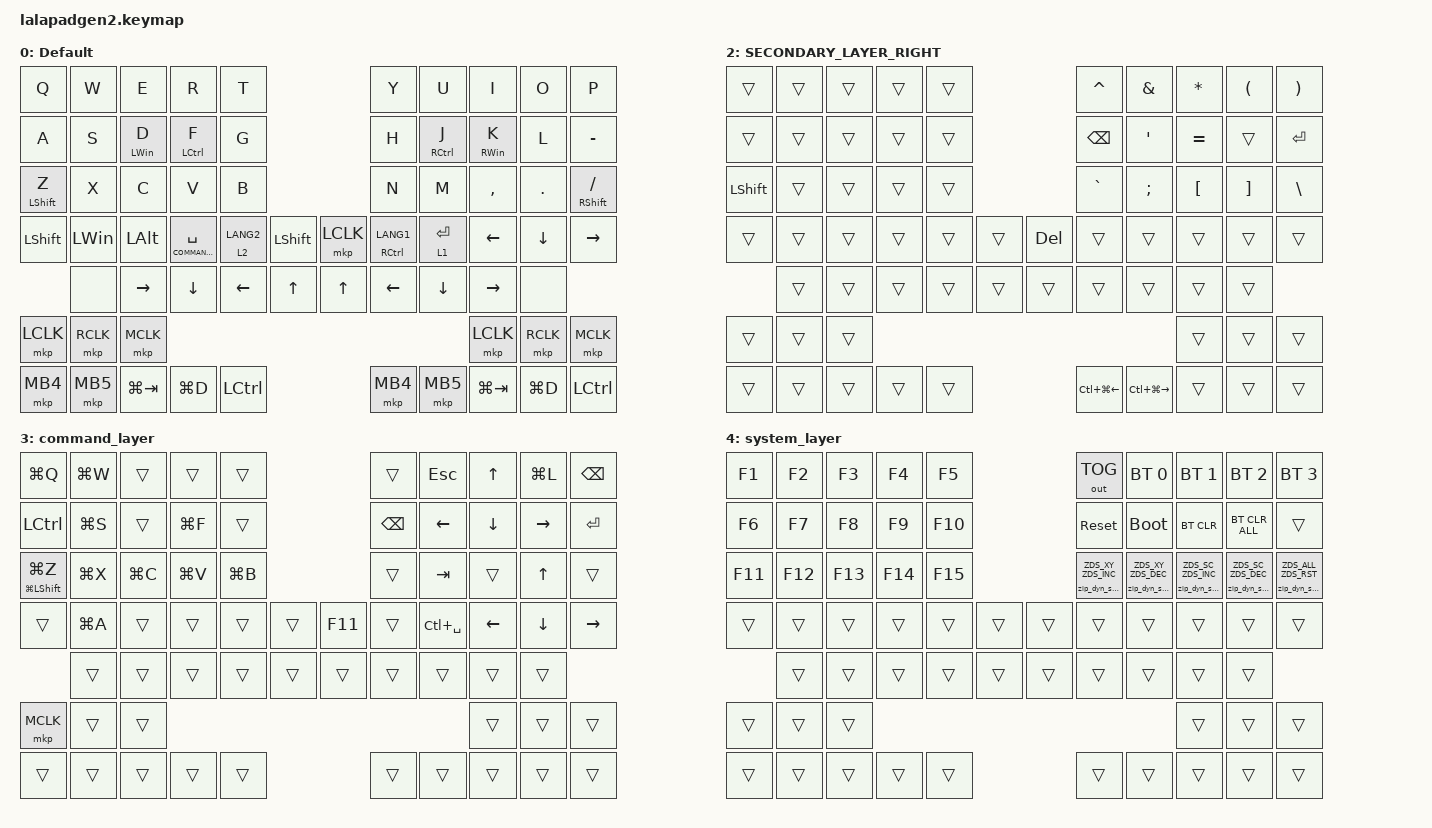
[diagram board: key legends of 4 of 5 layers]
#include <input/processors.dtsi>
#include <dt-bindings/zmk/zip_dynamic_scale.h>
#include <behaviors.dtsi>
#include <dt-bindings/zmk/bt.h>
#include <dt-bindings/zmk/keys.h>
#include <dt-bindings/zmk/outputs.h>
#include <dt-bindings/zmk/pointing.h>

#define DEFAULT_LAYER         0
#define SECONDARY_LAYER_LEFT  1
#define SECONDARY_LAYER_RIGHT 2
#define COMMAND_LAYER         3
#define SYSTEM_LAYER          4
#define LEFT_ALPHA_KEYS  0 1 2 3 4 10 11 12 13 14 20 21 22 23 24
#define RIGHT_ALPHA_KEYS 5 6 7 8 9 15 16 17 18 19 25 26 27 28 29

&mt { quick-tap-ms = <200>; };

&lt { quick-tap-ms = <200>; };

/ {
    behaviors {
        zip_dyn_scale: zip_dyn_scale {
            compatible = "zmk,behavior-zip-dynamic-scale";
            #binding-cells = <2>;
        };

        zip_dyn_scale_set: zip_dyn_scale_set {
            compatible = "zmk,behavior-zip-dynamic-scale-set";
            #binding-cells = <2>;
        };

        mt_hold: mt_hold {
            compatible = "zmk,behavior-hold-tap";
            #binding-cells = <2>;
            flavor = "hold-preferred";
            tapping-term-ms = <200>;
            quick-tap-ms = <200>;
            require-prior-idle-ms = <125>;
            bindings = <&kp>, <&kp>;
        };

        mt_tap: mt_tap {
            compatible = "zmk,behavior-hold-tap";
            #binding-cells = <2>;
            flavor = "tap-preferred";
            tapping-term-ms = <200>;
            quick-tap-ms = <200>;
            require-prior-idle-ms = <125>;
            bindings = <&kp>, <&kp>;
        };

        f_ctrl: f_ctrl {
            compatible = "zmk,behavior-hold-tap";
            #binding-cells = <2>;
            flavor = "balanced";
            tapping-term-ms = <280>;
            quick-tap-ms = <175>;
            require-prior-idle-ms = <150>;
            bindings = <&kp>, <&kp>;

            hold-trigger-key-positions = <RIGHT_ALPHA_KEYS>;
            hold-trigger-on-release;
        };

        z_shift: z_shift {
            compatible = "zmk,behavior-hold-tap";
            #binding-cells = <2>;
            flavor = "balanced";
            tapping-term-ms = <280>;
            quick-tap-ms = <175>;
            require-prior-idle-ms = <150>;
            bindings = <&kp>, <&kp>;

            hold-trigger-key-positions = <RIGHT_ALPHA_KEYS>;
            hold-trigger-on-release;
        };

        d_cmd: d_cmd {
            compatible = "zmk,behavior-hold-tap";
            #binding-cells = <2>;
            flavor = "balanced";
            tapping-term-ms = <280>;
            quick-tap-ms = <175>;
            require-prior-idle-ms = <150>;
            bindings = <&kp>, <&kp>;

            hold-trigger-key-positions = <RIGHT_ALPHA_KEYS>;
            hold-trigger-on-release;
        };

        j_ctrl: j_ctrl {
            compatible = "zmk,behavior-hold-tap";
            #binding-cells = <2>;
            flavor = "balanced";
            tapping-term-ms = <280>;
            quick-tap-ms = <175>;
            require-prior-idle-ms = <150>;
            bindings = <&kp>, <&kp>;

            hold-trigger-key-positions = <LEFT_ALPHA_KEYS>;
            hold-trigger-on-release;
        };

        slash_shift: slash_shift {
            compatible = "zmk,behavior-hold-tap";
            #binding-cells = <2>;
            flavor = "balanced";
            tapping-term-ms = <280>;
            quick-tap-ms = <175>;
            require-prior-idle-ms = <150>;
            bindings = <&kp>, <&kp>;

            hold-trigger-key-positions = <LEFT_ALPHA_KEYS>;
            hold-trigger-on-release;
        };

        k_cmd: k_cmd {
            compatible = "zmk,behavior-hold-tap";
            #binding-cells = <2>;
            flavor = "balanced";
            tapping-term-ms = <280>;
            quick-tap-ms = <175>;
            require-prior-idle-ms = <150>;
            bindings = <&kp>, <&kp>;

            hold-trigger-key-positions = <LEFT_ALPHA_KEYS>;
            hold-trigger-on-release;
        };

        mt_hold_on_other: mt_hold_on_other {
            compatible = "zmk,behavior-hold-tap";
            #binding-cells = <2>;
            flavor = "hold-preferred";
            tapping-term-ms = <500>;
            quick-tap-ms = <200>;
            bindings = <&kp>, <&kp>;
        };

        lt_hold_on_other: lt_hold_on_other {
            compatible = "zmk,behavior-hold-tap";
            #binding-cells = <2>;
            flavor = "hold-preferred";
            tapping-term-ms = <500>;
            quick-tap-ms = <200>;
            bindings = <&mo>, <&kp>;
        };

        lt_hold: lt_hold {
            compatible = "zmk,behavior-hold-tap";
            #binding-cells = <2>;
            flavor = "hold-preferred";
            tapping-term-ms = <200>;
            quick-tap-ms = <200>;
            require-prior-idle-ms = <125>;
            bindings = <&mo>, <&kp>;
        };

        tap_dance_layer_1and2: tap_dance_layer_1and2 {
            compatible = "zmk,behavior-tap-dance";
            label = "td_mo12";
            #binding-cells = <0>;
            bindings = <&mo 4>, <&mo 4>;
        };
    };

    combos {
        compatible = "zmk,combos";

        CONBO_ESC {
            bindings = <&kp ESCAPE>;
            key-positions = <0 1>;
        };

        COMBO_SYSTEM_LAYER {
            bindings = <&mo 4>;
            key-positions = <30 31>;
        };

        COMBO_UP_ARROW {
            bindings = <&kp UP_ARROW>;
            key-positions = <27 28>;
            layers = <0>;
            timeout-ms = <35>;
        };

        COMBO_BACKSPACE {
            bindings = <&kp BACKSPACE>;
            key-positions = <26 27>;
            layers = <0>;
            timeout-ms = <35>;
        };
    };

    keymap {
        compatible = "zmk,keymap";

        DEFAULT_LAYER {
            display-name = "Default";
            bindings = <
&kp Q                  &kp W      &kp E          &kp R                                 &kp T                                        &kp Y                         &kp U                    &kp I           &kp O           &kp P
&kp A                  &kp S      &d_cmd LWIN D  &f_ctrl LEFT_CONTROL F                &kp G                                        &kp H                         &j_ctrl RIGHT_CONTROL J  &k_cmd RWIN K   &kp L           &kp MINUS
&z_shift LEFT_SHIFT Z  &kp X      &kp C          &kp V                                 &kp B                                        &kp N                         &kp M                    &kp COMMA       &kp PERIOD      &slash_shift RIGHT_SHIFT SLASH
&kp LEFT_SHIFT         &kp LWIN   &kp LEFT_ALT   &lt_hold_on_other COMMAND_LAYER SPACE  &lt_hold 2 LANG2  &kp LEFT_SHIFT  &mkp LCLK  &mt_hold RIGHT_CONTROL LANG1  &lt_hold 1 ENTER         &kp LEFT_ARROW  &kp DOWN_ARROW  &kp RIGHT_ARROW
                       &none      &kp RIGHT      &kp DOWN                              &kp LEFT          &kp UP          &kp UP     &kp LEFT                      &kp DOWN                 &kp RIGHT       &none
&mkp LCLK              &mkp RCLK  &mkp MCLK                                                                                                                                                &mkp LCLK       &mkp RCLK       &mkp MCLK
&mkp MB4               &mkp MB5   &kp LG(TAB)    &kp LG(D)                             &kp LCTRL                                    &mkp MB4                      &mkp MB5                 &kp LG(TAB)     &kp LG(D)       &kp LCTRL
            >;
        };

        SECONDARY_LAYER_LEFT {
            display-name = "secondary_layer";
            bindings = <
&kp EXCLAMATION    &kp AT_SIGN   &kp HASH      &kp DOLLAR     &kp PERCENT                  &trans         &trans          &kp UP_ARROW    &trans           &trans
&kp NUMBER_1       &kp NUMBER_2  &kp NUMBER_3  &kp NUMBER_4   &kp N5                       &kp BACKSPACE  &kp LEFT_ARROW  &kp DOWN_ARROW  &kp RIGHT_ARROW  &kp ENTER
&kp NUMBER_6       &kp N7        &kp N8        &kp N9         &kp N0                       &trans         &kp TAB         &trans          &trans           &trans
&trans             &trans        &trans        &kp LC(SPACE)  &trans       &trans  &trans  &trans         &trans          &trans          &trans           &trans
                   &trans        &trans        &trans         &trans       &trans  &trans  &trans         &trans          &trans          &trans
&trans             &trans        &trans                                                                                   &trans          &trans           &kp LC(LG(LEFT))
&kp LC(LG(RIGHT))  &trans        &trans        &trans         &trans                       &trans         &trans          &trans          &trans
            >;
        };

        SECONDARY_LAYER_RIGHT {
            bindings = <
&trans          &trans  &trans  &trans  &trans                   &kp CARET         &kp AMPERSAND      &kp ASTERISK      &kp LEFT_PARENTHESIS  &kp RIGHT_PARENTHESIS
&trans          &trans  &trans  &trans  &trans                   &kp BACKSPACE     &kp SINGLE_QUOTE   &kp EQUAL         &trans                &kp ENTER
&kp LEFT_SHIFT  &trans  &trans  &trans  &trans                   &kp GRAVE         &kp SEMICOLON      &kp LEFT_BRACKET  &kp RIGHT_BRACKET     &kp BACKSLASH
&trans          &trans  &trans  &trans  &trans  &trans  &kp DEL  &trans            &trans             &trans            &trans                &trans
                &trans  &trans  &trans  &trans  &trans  &trans   &trans            &trans             &trans            &trans
&trans          &trans  &trans                                                                        &trans            &trans                &trans
&trans          &trans  &trans  &trans  &trans                   &kp LC(LG(LEFT))  &kp LC(LG(RIGHT))  &trans            &trans                &trans
            >;
        };

        COMMAND_LAYER {
            display-name = "command_layer";
            bindings = <
&kp LG(Q)                      &kp LG(W)  &trans     &trans     &trans                      &trans         &kp ESCAPE      &kp UP_ARROW    &kp LG(L)        &kp BACKSPACE
&kp LEFT_CONTROL               &kp LG(S)  &trans     &kp LG(F)  &trans                      &kp BACKSPACE  &kp LEFT_ARROW  &kp DOWN_ARROW  &kp RIGHT_ARROW  &kp ENTER
&mt_hold LG(LEFT_SHIFT) LG(Z)  &kp LG(X)  &kp LG(C)  &kp LG(V)  &kp LG(B)                   &trans         &kp TAB         &trans          &kp UP_ARROW     &trans
&trans                         &kp LG(A)  &trans     &trans     &trans     &trans  &kp F11  &trans         &kp LC(SPACE)   &kp LEFT_ARROW  &kp DOWN_ARROW   &kp RIGHT_ARROW
                               &trans     &trans     &trans     &trans     &trans  &trans   &trans         &trans          &trans          &trans
&mkp MCLK                      &trans     &trans                                                                           &trans          &trans           &trans
&trans                         &trans     &trans     &trans     &trans                      &trans         &trans          &trans          &trans           &trans
            >;
        };

        SYSTEM_LAYER {
            display-name = "system_layer";
            bindings = <
&kp F1   &kp F2   &kp F3   &kp F4   &kp F5                   &out OUT_TOG                   &bt BT_SEL 0                   &bt BT_SEL 1                   &bt BT_SEL 2                   &bt BT_SEL 3
&kp F6   &kp F7   &kp F8   &kp F9   &kp F10                  &sys_reset                     &bootloader                    &bt BT_CLR                     &bt BT_CLR_ALL                 &trans
&kp F11  &kp F12  &kp F13  &kp F14  &kp F15                  &zip_dyn_scale ZDS_XY ZDS_INC  &zip_dyn_scale ZDS_XY ZDS_DEC  &zip_dyn_scale ZDS_SC ZDS_INC  &zip_dyn_scale ZDS_SC ZDS_DEC  &zip_dyn_scale ZDS_ALL ZDS_RST
&trans   &trans   &trans   &trans   &trans   &trans  &trans  &trans                         &trans                         &trans                         &trans                         &trans
         &trans   &trans   &trans   &trans   &trans  &trans  &trans                         &trans                         &trans                         &trans
&trans   &trans   &trans                                                                                                   &trans                         &trans                         &trans
&trans   &trans   &trans   &trans   &trans                   &trans                         &trans                         &trans                         &trans                         &trans
            >;
        };
    };

    conditional_layers { compatible = "zmk,conditional-layers"; };
};
